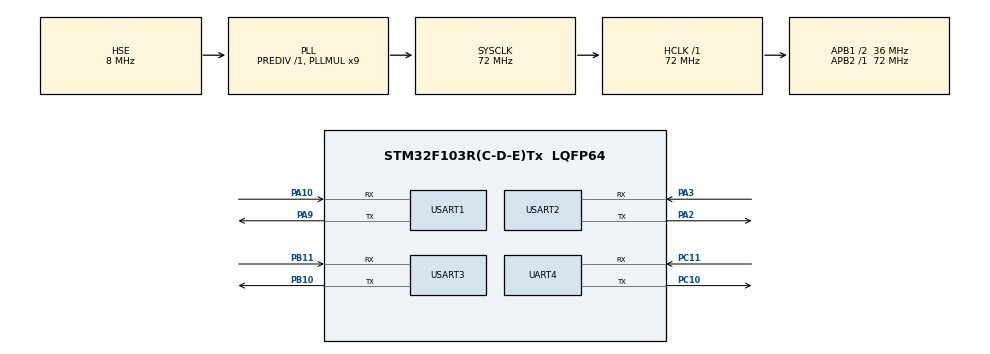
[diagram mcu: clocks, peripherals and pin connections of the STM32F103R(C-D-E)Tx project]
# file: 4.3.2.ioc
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Dma.Request0=USART3_RX
Dma.USART3_RX.0.Direction=DMA_PERIPH_TO_MEMORY
Dma.USART3_RX.0.Instance=DMA1_Channel3
Dma.USART3_RX.0.MemDataAlignment=DMA_MDATAALIGN_BYTE
Dma.USART3_RX.0.MemInc=DMA_MINC_ENABLE
Dma.USART3_RX.0.Mode=DMA_NORMAL
Dma.USART3_RX.0.PeriphDataAlignment=DMA_PDATAALIGN_BYTE
Dma.USART3_RX.0.PeriphInc=DMA_PINC_DISABLE
Dma.USART3_RX.0.Priority=DMA_PRIORITY_LOW
Mcu.Family=STM32F1
Mcu.Name=STM32F103R(C-D-E)Tx
Mcu.Package=LQFP64
NVIC.DMA1_Channel3_IRQn=true\:0\:0\:false\:false\:true\:false\:true\:true
NVIC.PriorityGroup=NVIC_PRIORITYGROUP_4
NVIC.USART1_IRQn=true\:0\:0\:false\:false\:true\:true\:true\:true
NVIC.USART3_IRQn=true\:0\:0\:false\:false\:true\:true\:true\:true
PA10.Mode=Asynchronous
PA10.Signal=USART1_RX
PA13.Mode=Serial_Wire
PA13.Signal=SYS_JTMS-SWDIO
PA14.Mode=Serial_Wire
PA14.Signal=SYS_JTCK-SWCLK
PA2.Mode=Asynchronous
PA2.Signal=USART2_TX
PA3.Mode=Asynchronous
PA3.Signal=USART2_RX
PA9.Mode=Asynchronous
PA9.Signal=USART1_TX
PB10.Mode=Asynchronous
PB10.Signal=USART3_TX
PB11.Mode=Asynchronous
PB11.Signal=USART3_RX
PC10.Mode=Asynchronous
PC10.Signal=UART4_TX
PC11.Mode=Asynchronous
PC11.Signal=UART4_RX
PD0-OSC_IN.Mode=HSE-External-Oscillator
PD0-OSC_IN.Signal=RCC_OSC_IN
PD1-OSC_OUT.Mode=HSE-External-Oscillator
PD1-OSC_OUT.Signal=RCC_OSC_OUT
ProjectManager.HeapSize=0x200
ProjectManager.StackSize=0x400
ProjectManager.TargetToolchain=MDK-ARM V5.32
RCC.AHBFreq_Value=72000000
RCC.APB1CLKDivider=RCC_HCLK_DIV2
RCC.APB1Freq_Value=36000000
RCC.APB1TimFreq_Value=72000000
RCC.APB2Freq_Value=72000000
RCC.APB2TimFreq_Value=72000000
RCC.HCLKFreq_Value=72000000
RCC.PLLMUL=RCC_PLL_MUL9
RCC.PLLSourceVirtual=RCC_PLLSOURCE_HSE
RCC.SYSCLKFreq_VALUE=72000000
RCC.SYSCLKSource=RCC_SYSCLKSOURCE_PLLCLK
RCC.USBFreq_Value=72000000
UART4.VirtualMode=Asynchronous
USART1.VirtualMode=VM_ASYNC
USART2.VirtualMode=VM_ASYNC
USART3.VirtualMode=VM_ASYNC
board=custom

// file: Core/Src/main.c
/* USER CODE BEGIN Header */
/**
  ******************************************************************************
  * @file           : main.c
  * @brief          : Main program body
  ******************************************************************************
  * @attention
  *
  * Copyright (c) 2024 STMicroelectronics.
  * All rights reserved.
  *
  * This software is licensed under terms that can be found in the LICENSE file
  * in the root directory of this software component.
  * If no LICENSE file comes with this software, it is provided AS-IS.
  *
  ******************************************************************************
  */
/* USER CODE END Header */
#include "main.h"
#include "dma.h"
#include "usart.h"
#include "gpio.h"

void SystemClock_Config(void);

	int flag,color;

void grab_all_up(int direction){//初始位置，全2048
	for(int i=0;i<3;i++){
	bus_servo_control(0,direction,3000);
	bus_servo_control(1,2000,3000);
	bus_servo_control(2,2048,3000);
	bus_servo_control(3,2048,3000);
	}

}

void grab_all_down_first(int direction){//抓取中间态1
	for(int i=0;i<3;i++){
		bus_servo_control(0,direction,6000);
		bus_servo_control(1,2000,6000);
		bus_servo_control(2,2548,6000);
		bus_servo_control(3,2050,6000);
	}

}

void grab_all_down(int direction){//抓取中间态结束
	for(int i=0;i<3;i++){
		bus_servo_control(0,direction,6000);
		bus_servo_control(1,300,6000);
		bus_servo_control(2,2548,6000);
		bus_servo_control(3,1048,6000);
	}

}

void put_all_first(int direction){	//一级放
	for(int i=0;i<3;i++){
	bus_servo_control(0,direction,2000);
	bus_servo_control(1,2048,2000);
	bus_servo_control(2,3200,2000);
	bus_servo_control(3,2700,2000);
	}
}

void put_all_second(int direction){	//抓取时状态
	for(int i=0;i<3;i++){
	bus_servo_control(0,direction,2000);
	bus_servo_control(1,3050,2000);
	bus_servo_control(2,2050,2000);
	bus_servo_control(3,2700,2000);
	}
}

void put_all_third(int direction){	//放置最终态
	for(int i=0;i<3;i++){
	bus_servo_control(0,direction,4000);
	bus_servo_control(1,2550,4000);
	bus_servo_control(2,2200,4000);
	bus_servo_control(3,2850,4000);
	}
}

void catch_all(){
	grab_all_up(850);
	delay_ms(2000);
	bus_servo_control(4,2048,2000);
	delay_ms(2000);
	put_all_first(850);
	delay_ms(2000);

	put_all_second(850);
	delay_ms(2000);
	flag = Openmv.m;
	bus_servo_control(4,3025,2000);//夹爪力度
	delay_ms(2000);
	grab_all_down(850);
	delay_ms(5000);

}

void put_three(int i){
	int direction;
	switch(i){
		case 1:direction = 2900;break;//红位置
		case 0:direction = 3300;break;//绿
		case 2:direction = 3700;break;//蓝
	}
	grab_all_down(direction);
	delay_ms(2000);
	put_all_third(direction);
	delay_ms(4000);
	bus_servo_control(4,2048,2000);
	delay_ms(2000);
	put_all_first(direction);
	delay_ms(2000);
	grab_all_up(direction);
	delay_ms(6000);

}

int main(void)
{

  /* MCU Configuration--------------------------------------------------------*/

  /* Reset of all peripherals, Initializes the Flash interface and the Systick. */
  HAL_Init();

  /* Configure the system clock */
  SystemClock_Config();

  /* Initialize all configured peripherals */
  MX_GPIO_Init();
  MX_DMA_Init();
  MX_USART1_UART_Init();
  MX_USART3_UART_Init();
  MX_UART4_Init();
  MX_USART2_UART_Init();
  /* USER CODE BEGIN 2 */
	delay_init(168);
	OpenmvInit();

	//flag = 1;
/* USER CODE END 2 */
	for(int i=0;i<3;i++){
		delay_ms(2000);
		catch_all();

		switch(flag){
			case 1:put_three(0);break;
			case 0:put_three(2);break;
			case 2:put_three(1);break;
		}
	}
	/*
	grab_all_up(850);
	delay_ms(2000);
	grab_all_down(850);
*/
//	grab_all_up(3300);
//	delay_ms(2000);
//	put_all_third(3300);

	//put_all_second(850);
	//bus_servo_control(4,2525,2000);
	//delay_ms(2000);

//	grab_all_up(850);
//	delay_ms(2000);
//	put_all_first(850);
//	delay_ms(2000);
//	put_all_second(850);
//	delay_ms(2000);

	//grab_all(2800);
	//put_all_first(850);
	//bus_servo_control(4,3048,2000);
  while (1)
  {

	  delay_ms(10);
  }
}

void SystemClock_Config(void)
{
  RCC_OscInitTypeDef RCC_OscInitStruct = {0};
  RCC_ClkInitTypeDef RCC_ClkInitStruct = {0};

  /** Initializes the RCC Oscillators according to the specified parameters
  * in the RCC_OscInitTypeDef structure.
  */
  RCC_OscInitStruct.OscillatorType = RCC_OSCILLATORTYPE_HSE;
  RCC_OscInitStruct.HSEState = RCC_HSE_ON;
  RCC_OscInitStruct.HSEPredivValue = RCC_HSE_PREDIV_DIV1;
  RCC_OscInitStruct.HSIState = RCC_HSI_ON;
  RCC_OscInitStruct.PLL.PLLState = RCC_PLL_ON;
  RCC_OscInitStruct.PLL.PLLSource = RCC_PLLSOURCE_HSE;
  RCC_OscInitStruct.PLL.PLLMUL = RCC_PLL_MUL9;
  if (HAL_RCC_OscConfig(&RCC_OscInitStruct) != HAL_OK)
  {
    Error_Handler();
  }

  /** Initializes the CPU, AHB and APB buses clocks
  */
  RCC_ClkInitStruct.ClockType = RCC_CLOCKTYPE_HCLK|RCC_CLOCKTYPE_SYSCLK
                              |RCC_CLOCKTYPE_PCLK1|RCC_CLOCKTYPE_PCLK2;
  RCC_ClkInitStruct.SYSCLKSource = RCC_SYSCLKSOURCE_PLLCLK;
  RCC_ClkInitStruct.AHBCLKDivider = RCC_SYSCLK_DIV1;
  RCC_ClkInitStruct.APB1CLKDivider = RCC_HCLK_DIV2;
  RCC_ClkInitStruct.APB2CLKDivider = RCC_HCLK_DIV1;

  if (HAL_RCC_ClockConfig(&RCC_ClkInitStruct, FLASH_LATENCY_2) != HAL_OK)
  {
    Error_Handler();
  }
}

void Error_Handler(void)
{
  __disable_irq();
  while (1)
  {
  }
}
